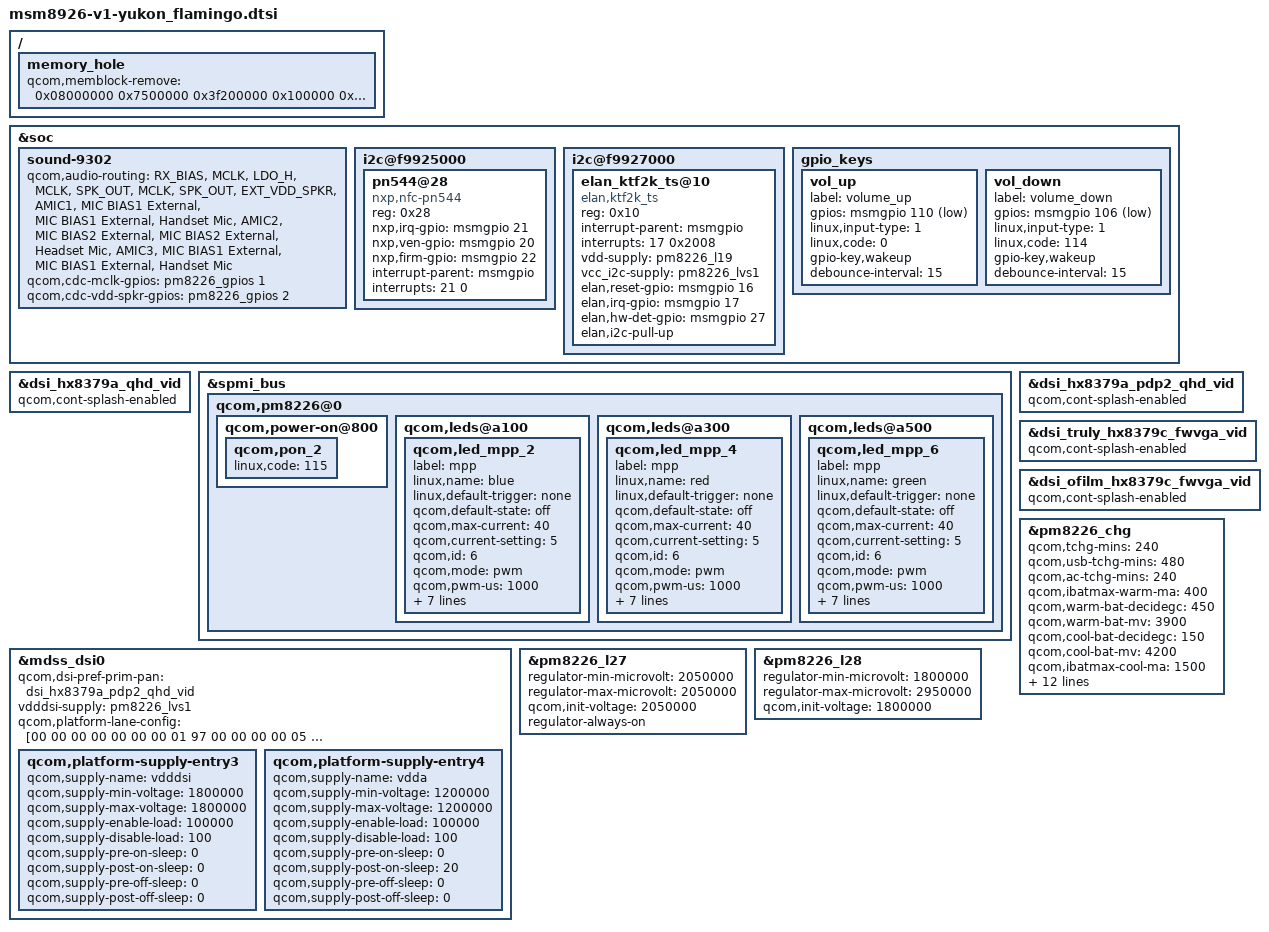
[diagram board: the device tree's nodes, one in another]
#include "msm8226-arima.dtsi"
#include "dsi-panel-truly-hx8379a-qhd-video.dtsi"

&soc {
	sound-9302 {
		qcom,audio-routing =
			"RX_BIAS", "MCLK",
			"LDO_H", "MCLK",
			"SPK_OUT", "MCLK",
			"SPK_OUT", "EXT_VDD_SPKR",
			"AMIC1", "MIC BIAS1 External",
			"MIC BIAS1 External", "Handset Mic",
			"AMIC2", "MIC BIAS2 External",
			"MIC BIAS2 External", "Headset Mic",
			"AMIC3", "MIC BIAS1 External",
			"MIC BIAS1 External", "Handset Mic";

		qcom,cdc-mclk-gpios = <&pm8226_gpios 1 0>;
		qcom,cdc-vdd-spkr-gpios = <&pm8226_gpios 2 0>;
	};
};

&soc {
	i2c@f9925000 { 
		pn544@28 {
			compatible = "nxp,nfc-pn544";
			reg = <0x28>;
			nxp,irq-gpio = <&msmgpio 21 0x00>;
			nxp,ven-gpio = <&msmgpio 20 0x00>;
			nxp,firm-gpio = <&msmgpio 22 0x00>;
			interrupt-parent = <&msmgpio>;
			interrupts = <21 0>;
		};
	};

    i2c@f9927000 { 
		elan_ktf2k_ts@10{
			compatible = "elan,ktf2k_ts";
			reg = <0x10>;
			interrupt-parent = <&msmgpio>;
			interrupts = <17 0x2008>;
			vdd-supply = <&pm8226_l19>;
			vcc_i2c-supply = <&pm8226_lvs1>;
			elan,reset-gpio = <&msmgpio 16 0x00>;
			elan,irq-gpio = <&msmgpio 17 0x2008>;
			elan,hw-det-gpio = <&msmgpio 27 0x00>;			
			elan,i2c-pull-up;
		};
    };
};


&dsi_hx8379a_qhd_vid { 
	qcom,cont-splash-enabled;
};

/ {
	memory_hole: memory_hole {
		qcom,memblock-remove = <0x08000000 0x7500000
			0x3f200000 0x100000
			0x0fa00000 0x500000>;
	};
};

#include "dsi-panel-truly-hx8379a-pdp2-qhd-video.dtsi"
#include "dsi-panel-truly-hx8379c-fwvga-video.dtsi"
#include "dsi-panel-ofilm-hx8379c-fwvga-video.dtsi"

&spmi_bus {
	qcom,pm8226@0 {
		qcom,power-on@800 {
			qcom,pon_2 {
				linux,code = <115>;
			};
		};
	};
};


&dsi_hx8379a_pdp2_qhd_vid {
	qcom,cont-splash-enabled;
};

&dsi_truly_hx8379c_fwvga_vid {
	qcom,cont-splash-enabled;
};

&dsi_ofilm_hx8379c_fwvga_vid {
	qcom,cont-splash-enabled;
};

&soc {
	gpio_keys {
		vol_up {
			label = "volume_up";
			gpios = <&msmgpio 110 0x1>;
			linux,input-type = <1>;
			linux,code = <0>;
			gpio-key,wakeup;
			debounce-interval = <15>;
		};
		
		vol_down {
			label = "volume_down";
			gpios = <&msmgpio 106 0x1>;
			linux,input-type = <1>;
			linux,code = <114>;
			gpio-key,wakeup;
			debounce-interval = <15>;
		};
	};
};

&mdss_dsi0 {
	qcom,dsi-pref-prim-pan = <&dsi_hx8379a_pdp2_qhd_vid>;
	vdddsi-supply = <&pm8226_lvs1>;
	qcom,platform-lane-config = [00 00 00 00 00 00 00 01 97
		00 00 00 00 05 00 00 01 97
		00 00 00 00 0a 00 00 01 97
		00 00 00 00 0f 00 00 01 97
		00 c0 00 00 00 00 00 01 bb];
	qcom,platform-supply-entry3 {
		qcom,supply-name = "vdddsi";
		qcom,supply-min-voltage = <1800000>;
		qcom,supply-max-voltage = <1800000>;
		qcom,supply-enable-load = <100000>;
		qcom,supply-disable-load = <100>;
		qcom,supply-pre-on-sleep = <0>;
		qcom,supply-post-on-sleep = <0>;
		qcom,supply-pre-off-sleep = <0>;
		qcom,supply-post-off-sleep = <0>;
	};
	qcom,platform-supply-entry4 {
		qcom,supply-name = "vdda";
		qcom,supply-min-voltage = <1200000>;
		qcom,supply-max-voltage = <1200000>;
		qcom,supply-enable-load = <100000>;
		qcom,supply-disable-load = <100>;
		qcom,supply-pre-on-sleep = <0>;
		qcom,supply-post-on-sleep = <20>;
		qcom,supply-pre-off-sleep = <0>;
		qcom,supply-post-off-sleep = <0>;
	};
};


&pm8226_chg {
	qcom,tchg-mins = <240>;
	qcom,usb-tchg-mins = <480>;
	qcom,ac-tchg-mins = <240>;
	qcom,ibatmax-warm-ma = <400>;
	qcom,warm-bat-decidegc = <450>;
	qcom,warm-bat-mv = <3900>;
	qcom,cool-bat-decidegc = <150>;
	qcom,cool-bat-mv = <4200>;
	qcom,ibatmax-cool-ma = <1500>;
	qcom,btc-disabled;
	qcom,hot-bat-decidegc = <550>;
	qcom,cold-bat-decidegc = <50>;
	qcom,charging-timer-enable;
	qcom,vbatweak-mv = <3400>;
	qcom,call-bat-mv = <3900>;
	qcom,resume-soc = <0>;
	qcom,vbatdet-delta-mv = <50>;
	qcom,first-maintain-mins = <3600>;
	qcom,second-maintain-mins = <12000>;
	qcom,first-maintain-mv = <4150>;
	qcom,second-maintain-mv = <4100>;
};

&spmi_bus {
	qcom,pm8226@0 {
		qcom,leds@a100 {
			status = "okay";
			qcom,led_mpp_2 {
				label = "mpp";
				linux,name = "blue";
				linux,default-trigger = "none";
				qcom,default-state = "off";
				qcom,max-current = <40>;
				qcom,current-setting = <5>;
				qcom,id = <6>;
				qcom,mode = "pwm";
				qcom,pwm-us = <1000>;
				qcom,source-sel = <14>;
				qcom,mode-ctrl = <0x60>;
				qcom,pwm-channel = <3>;
				qcom,start-idx = <40>;
				qcom,ramp-step-ms = <120>;
				qcom,duty-pcts = [00 00 50 99 99 99 50 00];
				qcom,use-blink;
			};
		};

		qcom,leds@a300 {
			status = "okay";
			qcom,led_mpp_4 {
				label = "mpp";
				linux,name = "red";
				linux,default-trigger = "none";
				qcom,default-state = "off";
				qcom,max-current = <40>;
				qcom,current-setting = <5>;
				qcom,id = <6>;
				qcom,mode = "pwm";
				qcom,pwm-us = <1000>;
				qcom,source-sel = <8>;
				qcom,mode-ctrl = <0x60>;
				qcom,pwm-channel = <0>;
				qcom,start-idx = <20>;
				qcom,ramp-step-ms = <120>;
				qcom,duty-pcts = [00 00 50 99 99 99 50 00];
				qcom,use-blink;
			};
		};

		qcom,leds@a500 {
			status = "okay";
			qcom,led_mpp_6 {
				label = "mpp";
				linux,name = "green";
				linux,default-trigger = "none";
				qcom,default-state = "off";
				qcom,max-current = <40>;
				qcom,current-setting = <5>;
				qcom,id = <6>;
				qcom,mode = "pwm";
				qcom,pwm-us = <1000>;
				qcom,mode-ctrl = <0x60>;
				qcom,source-sel = <10>;
				qcom,pwm-channel = <5>;
				qcom,start-idx = <1>;
				qcom,ramp-step-ms = <120>;
				qcom,duty-pcts = [00 00 50 99 99 99 50 00];
				qcom,use-blink;
			};
		};
	};
};

&pm8226_l27{
	regulator-min-microvolt = <2050000>;
	regulator-max-microvolt = <2050000>;
	qcom,init-voltage = <2050000>;
	regulator-always-on;
};

&pm8226_l28{
	regulator-min-microvolt = <1800000>;
	regulator-max-microvolt = <2950000>;
	qcom,init-voltage = <1800000>;
};
